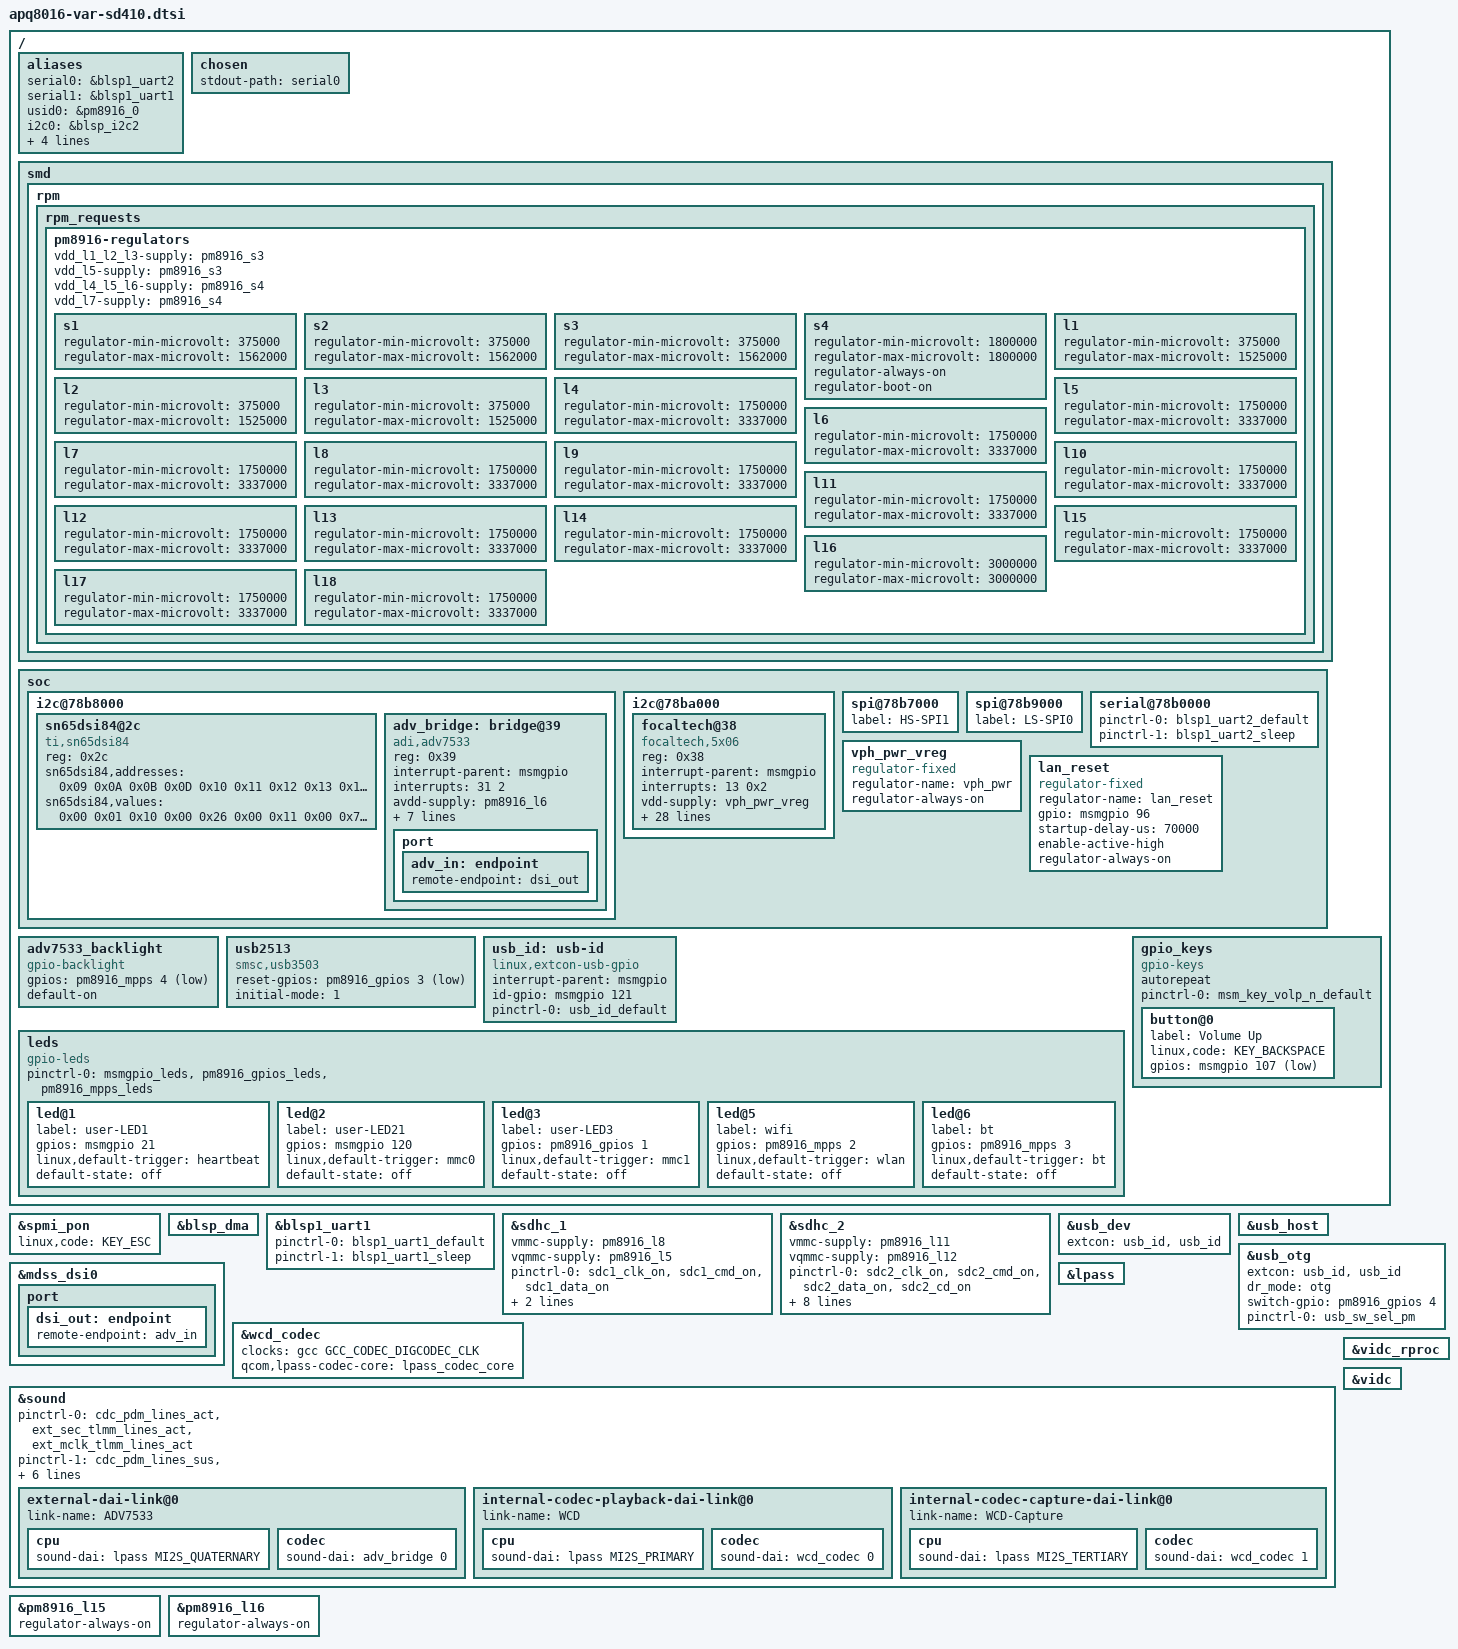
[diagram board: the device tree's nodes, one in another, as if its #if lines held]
/*
/*
 * Copyright (c) 2015, The Linux Foundation. All rights reserved.
 *
 * This program is free software; you can redistribute it and/or modify
 * it under the terms of the GNU General Public License version 2 and
 * only version 2 as published by the Free Software Foundation.
 *
 * This program is distributed in the hope that it will be useful,
 * but WITHOUT ANY WARRANTY; without even the implied warranty of
 * MERCHANTABILITY or FITNESS FOR A PARTICULAR PURPOSE.  See the
 * GNU General Public License for more details.
 */
/* #define HDMI_DISPLAY */
#include <dt-bindings/gpio/gpio.h>
#include <dt-bindings/input/input.h>
#include <dt-bindings/sound/apq8016-lpass.h>
#include "msm8916.dtsi"
#include "pm8916.dtsi"
#include "apq8016-var-sd410-soc-pins.dtsi"
#include "apq8016-var-sd410-pmic-pins.dtsi"
#include "msm8916-mdss.dtsi"
/ {
	aliases {
		serial0 = &blsp1_uart2;
		serial1 = &blsp1_uart1;
		usid0 = &pm8916_0;
		i2c0	= &blsp_i2c2;
		i2c1	= &blsp_i2c6;
		i2c3	= &blsp_i2c4;
		spi0	= &blsp_spi5;
		spi1	= &blsp_spi3;
	};

	chosen {
		stdout-path = "serial0";
	};

	smd {
		rpm {
			rpm_requests {
				pm8916-regulators {

					vdd_l1_l2_l3-supply = <&pm8916_s3>;
					vdd_l5-supply = <&pm8916_s3>;
					vdd_l4_l5_l6-supply = <&pm8916_s4>;
					vdd_l7-supply = <&pm8916_s4>;

					s1 {
						regulator-min-microvolt = <375000>;
						regulator-max-microvolt = <1562000>;
						
					};
					s2 {
						regulator-min-microvolt = <375000>;
						regulator-max-microvolt = <1562000>;
						
					};
					s3 {
						regulator-min-microvolt = <375000>;
						regulator-max-microvolt = <1562000>;
						
					};
					s4 {
						regulator-min-microvolt = <1800000>;
						regulator-max-microvolt = <1800000>;
						
						regulator-always-on;
						regulator-boot-on;
					};

					l1 {
						regulator-min-microvolt = <375000>;
						regulator-max-microvolt = <1525000>;
						
					};
					l2 {
						regulator-min-microvolt = <375000>;
						regulator-max-microvolt = <1525000>;
						
					};
					l3 {
						regulator-min-microvolt = <375000>;
						regulator-max-microvolt = <1525000>;
						
					};
					l4 {
						regulator-min-microvolt = <1750000>;
						regulator-max-microvolt = <3337000>;
						
					};
					l5 {
						regulator-min-microvolt = <1750000>;
						regulator-max-microvolt = <3337000>;
						
					};
					l6 {
						regulator-min-microvolt = <1750000>;
						regulator-max-microvolt = <3337000>;
						
					};
					l7 {
						regulator-min-microvolt = <1750000>;
						regulator-max-microvolt = <3337000>;
						
					};
					l8 {
						regulator-min-microvolt = <1750000>;
						regulator-max-microvolt = <3337000>;
						
					};
					l9 {
						regulator-min-microvolt = <1750000>;
						regulator-max-microvolt = <3337000>;
						
					};
					l10 {
						regulator-min-microvolt = <1750000>;
						regulator-max-microvolt = <3337000>;
						
					};
					l11 {
						regulator-min-microvolt = <1750000>;
						regulator-max-microvolt = <3337000>;
						
					};
					l12 {
						regulator-min-microvolt = <1750000>;
						regulator-max-microvolt = <3337000>;
						
					};
					l13 {
						regulator-min-microvolt = <1750000>;
						regulator-max-microvolt = <3337000>;
						
					};
					l14 {
						regulator-min-microvolt = <1750000>;
						regulator-max-microvolt = <3337000>;
						
					};
					l15 {
						regulator-min-microvolt = <1750000>;
						regulator-max-microvolt = <3337000>;
						
					};
					l16 {
						regulator-min-microvolt = <3000000>;
						regulator-max-microvolt = <3000000>;
						
					};
					l17 {
						regulator-min-microvolt = <1750000>;
						regulator-max-microvolt = <3337000>;
						
					};
					l18 {
						regulator-min-microvolt = <1750000>;
						regulator-max-microvolt = <3337000>;
						
					};
				};
			};
		};
	};

	soc {
		i2c@78b8000 {
			status = "ok";
			sn65dsi84@2c {
				status = "ok";
				compatible = "ti,sn65dsi84";
				reg = <0x2c>;
				sn65dsi84,addresses = <	0x09 0x0A 0x0B 0x0D 0x10 0x11 0x12 0x13 
										0x18 0x19 0x1A 0x1B 0x20 0x21 0x22 0x23 
										0x24 0x25 0x26 0x27 0x28 0x29 0x2A 0x2B 
										0x2C 0x2D 0x2E 0x2F 0x30 0x31 0x32 0x33 
										0x34 0x35 0x36 0x37 0x38 0x39 0x3A 0x3B 
										0x3C 0x3D 0x3E 0x0D>;
				sn65dsi84,values =    <	0x00 0x01 0x10 0x00 0x26 0x00 0x11 0x00 
										0x7a 0x00 0x03 0x00 0x20 0x03 0x00 0x00 
										0x00 0x00 0x00 0x00 0x21 0x00 0x00 0x00 
										0x30 0x00 0x00 0x00 0x03 0x00 0x00 0x00 
										0x28 0x00 0x00 0x00 0x00 0x00 0x00 0x00 
										0x00 0x00 0x00 0x01>;
			};
			
#ifdef HDMI_DISPLAY
			adv_bridge: bridge@39 {
				status = "ok";
				compatible = "adi,adv7533";
				reg = <0x39>;
				interrupt-parent = <&msmgpio>;
				interrupts = <31 2>;
				avdd-supply = <&pm8916_l6>;
				v3p3-supply = <&pm8916_l17>;
				adi,dsi-lanes = <4>;
				pd-gpios = <&msmgpio 32 0>;
				pinctrl-names = "default","sleep";
				pinctrl-0 = <&adv7533_int_active &adv7533_switch_active>;
				pinctrl-1 = <&adv7533_int_suspend &adv7533_switch_suspend>;
				#sound-dai-cells = <1>;

				port {
					adv_in: endpoint {
						remote-endpoint = <&dsi_out>;
					};
				};

			};
#endif
		};

		i2c@78ba000 {
			status = "ok";
			focaltech@38{
				compatible = "focaltech,5x06";
				reg = <0x38>;
				interrupt-parent = <&msmgpio>;
				interrupts = <13 0x2>;
				vdd-supply = <&vph_pwr_vreg>;
				vcc_i2c-supply = <&vph_pwr_vreg>;
				pinctrl-names = "pmx_ts_active","pmx_ts_suspend";
				pinctrl-0 = <&pmx_ts_int_active &pmx_ts_reset_active>;
				pinctrl-1 = <&pmx_ts_int_suspend &pmx_ts_reset_suspend>;
				focaltech,name = "ft5x06";
				focaltech,family-id = <0x54>;
				focaltech,reset-gpio = <&msmgpio 12 0x00>;
				focaltech,irq-gpio = <&msmgpio 13 0x00>;
				focaltech,display-coords = <0 0 800 480>;
				focaltech,hard-reset-delay-ms = <50>;
				focaltech,soft-reset-delay-ms = <50>;
				focaltech,no-force-update;
				focaltech,i2c-pull-up;
				focaltech,group-id = <1>;
				focaltech,hard-reset-delay = <20>;
				focaltech,soft-reset-delay = <150>;
				focaltech,num-max-touches = <2>;
				focaltech,fw-name = "ft_8610_qrd_fw.bin";
				focaltech,fw-delay-aa-ms = <100>;
				focaltech,fw-delay-55-ms = <30>;
				focaltech,fw-upgrade-id1 = <0x79>;
				focaltech,fw-upgrade-id2 = <0x08>;
				focaltech,fw-delay-readid-ms = <10>;
				focaltech,fw-delay-era-flsh-ms = <2000>;
				focaltech,fw-auto-cal;
				focaltech,mirror_h;
				focaltech,mirror_v;
			};
		};

		spi@78b7000 {
			label = "HS-SPI1";
			status = "okay";
		};

		spi@78b9000 {
			label = "LS-SPI0";
			status = "okay";
		};
		serial@78b0000 {
			status = "okay";
			pinctrl-names = "default", "sleep";
			pinctrl-0 = <&blsp1_uart2_default>;
			pinctrl-1 = <&blsp1_uart2_sleep>;
		};
		vph_pwr_vreg: vph_pwr_vreg {

			compatible = "regulator-fixed";
			regulator-name = "vph_pwr";
			status = "ok";
			regulator-always-on;
		}; 
		lan_reset: lan_reset {

			compatible = "regulator-fixed";
			regulator-name = "lan_reset";
	                gpio = <&msmgpio 96 GPIO_ACTIVE_HIGH>;
			startup-delay-us = <70000>;
			enable-active-high;
			regulator-always-on;
			status = "ok";
		}; 
	};
#ifdef HDMI_DISPLAY
	adv7533_backlight: adv7533_backlight {
		compatible = "gpio-backlight";
		gpios = <&pm8916_mpps 4 GPIO_ACTIVE_LOW>;
		default-on;
	};
#else
	backlight: backlight {
		compatible = "gpio-backlight";
		gpios = <&pm8916_mpps 4 GPIO_ACTIVE_HIGH>;
		default-on;
	};
#endif

	usb2513 {
		compatible = "smsc,usb3503";
		reset-gpios = <&pm8916_gpios 3 GPIO_ACTIVE_LOW>;
		initial-mode = <1>;
	};

	usb_id: usb-id {
		interrupt-parent = <&msmgpio>;
		compatible = "linux,extcon-usb-gpio";
		id-gpio = <&msmgpio 121 GPIO_ACTIVE_HIGH>;
		pinctrl-names = "default";
		pinctrl-0 = <&usb_id_default>;
	};

	leds {
		pinctrl-names = "default";
		pinctrl-0 = <&msmgpio_leds>,
			    <&pm8916_gpios_leds>,
			    <&pm8916_mpps_leds>;

		compatible = "gpio-leds";

		led@1 {
			label = "user-LED1";
			gpios = <&msmgpio 21 GPIO_ACTIVE_HIGH>;
			linux,default-trigger = "heartbeat";
			default-state = "off";
		};

		led@2 {
			label = "user-LED21";
			gpios = <&msmgpio 120 GPIO_ACTIVE_HIGH>;
			linux,default-trigger = "mmc0";
			default-state = "off";
		};

		led@3 {
			label = "user-LED3";
			gpios = <&pm8916_gpios 1 GPIO_ACTIVE_HIGH>;
			linux,default-trigger = "mmc1";
			default-state = "off";
		};

		led@5 {
			label = "wifi";
			gpios = <&pm8916_mpps 2 GPIO_ACTIVE_HIGH>;
			linux,default-trigger = "wlan";
			default-state = "off";
		};

		led@6 {
			label = "bt";
			gpios = <&pm8916_mpps 3 GPIO_ACTIVE_HIGH>;
			linux,default-trigger = "bt";
			default-state = "off";
		};
	};

	gpio_keys {
		compatible = "gpio-keys";
		#address-cells = <1>;
		#size-cells = <0>;
		autorepeat;

		pinctrl-names = "default";
		pinctrl-0 = <&msm_key_volp_n_default>;

		button@0 {
			label = "Volume Up";
			linux,code = <KEY_BACKSPACE>;
			gpios = <&msmgpio 107 GPIO_ACTIVE_LOW>;
		};
	};

};

&spmi_pon {
	// Overwrite RESETIN_N keyboard scan code
	linux,code = <KEY_ESC>;
};

&blsp_dma {
	status = "okay";
};

&blsp1_uart1 {
	status = "okay";
	pinctrl-names = "default", "sleep";
	pinctrl-0 = <&blsp1_uart1_default>;
	pinctrl-1 = <&blsp1_uart1_sleep>;
};

&sdhc_1 {
	vmmc-supply = <&pm8916_l8>;
	vqmmc-supply = <&pm8916_l5>;

	pinctrl-names = "default", "sleep";
	pinctrl-0 = <&sdc1_clk_on &sdc1_cmd_on &sdc1_data_on>;
	pinctrl-1 = <&sdc1_clk_off &sdc1_cmd_off &sdc1_data_off>;
	status = "okay";
};

&sdhc_2 {
	vmmc-supply = <&pm8916_l11>;
	vqmmc-supply = <&pm8916_l12>;

	pinctrl-names = "default", "sleep";
	pinctrl-0 = <&sdc2_clk_on &sdc2_cmd_on &sdc2_data_on &sdc2_cd_on>;
	pinctrl-1 = <&sdc2_clk_off &sdc2_cmd_off &sdc2_data_off &sdc2_cd_off>;
	#address-cells = <0>;
	interrupt-parent = <&sdhc_2>;
	interrupts = <0 1 2>;
	#interrupt-cells = <1>;
	interrupt-map-mask = <0xffffffff>;
	interrupt-map = <0 &intc 0 125 0
			1 &intc 0 221 0
			2 &msmgpio 38 0>;
	interrupt-names = "hc_irq", "pwr_irq", "status_irq";
	cd-gpios = <&msmgpio 38 0x1>;

	status = "okay";
};

&usb_dev {
	extcon = <&usb_id>, <&usb_id>;
	status = "okay";
};

&usb_host {
	status = "okay";
};

&sdhc_1 {
	status = "okay";
};

&usb_otg {
	extcon = <&usb_id>, <&usb_id>;
	dr_mode = "otg";
	status = "okay";
	switch-gpio = <&pm8916_gpios 4 GPIO_ACTIVE_HIGH>; // D+/D- lines: 1 - Routed to HUB, 0 - Device
	pinctrl-names = "default";
	pinctrl-0 = <&usb_sw_sel_pm>;
};

#ifdef HDMI_DISPLAY
&mdss_dsi0 {
	status = "ok";

	port {
		dsi_out: endpoint {
			remote-endpoint = <&adv_in>;
		};
	};
};
#else
&mdss_dsi0 {
 	status = "ok";
	panel1:panel@0{
		reg = <0>;
		status = "ok";
		compatible = "sgd,gktw70sdae4sd";
		backlight = <&backlight>;
		
		enable-gpios =<&msmgpio 32 GPIO_ACTIVE_HIGH>;
		pinctrl-names = "default","sleep";
		pinctrl-0 = <&adv7533_switch_active>;
		pinctrl-1 = <&adv7533_switch_suspend>;

		port {
			panel_in: endpoint {
				remote-endpoint = <&dsi0_out>;
			};
		};
	};

	port {
		dsi0_out: endpoint {
			remote-endpoint = <&panel_in>;
		};
	};
};
#endif

&lpass {
	status = "okay";
};

&wcd_codec {
	status = "okay";
	clocks = <&gcc GCC_CODEC_DIGCODEC_CLK>;
	clock-names = "mclk";
	qcom,lpass-codec-core = <&lpass_codec_core>;
};
	/*
	Internal Codec
		playback - Primary MI2S
		capture - Ter MI2S

	External Primary:
		playback - secondary MI2S
		capture - Quat MI2S

	External Secondary:
		playback - Quat MI2S
		capture - Quat MI2S

	*/
&sound {
	status = "okay";
	pinctrl-0 = <&cdc_pdm_lines_act &ext_sec_tlmm_lines_act &ext_mclk_tlmm_lines_act>;
	pinctrl-1 = <&cdc_pdm_lines_sus &ext_sec_tlmm_lines_sus &ext_mclk_tlmm_lines_sus>;
	pinctrl-names = "default", "sleep";
	qcom,model = "DB410c";
	qcom,audio-routing =
		"AMIC1", "MIC BIAS External",
		"AMIC2", "MIC BIAS Internal2",
		"AMIC3", "MIC BIAS External",
		"DMIC1", "MIC BIAS Internal1";

#ifdef HDMI_DISPLAY
	/* External Primary or External Secondary -ADV7533 HDMI */
	external-dai-link@0 {
		link-name = "ADV7533";

		cpu { /* QUAT */
			sound-dai = <&lpass MI2S_QUATERNARY>;
		};
		codec {
			sound-dai = <&adv_bridge 0>;
		};
	};
#endif
	internal-codec-playback-dai-link@0 {		/* I2S - Internal codec */
		link-name = "WCD";
		cpu { /* PRIMARY */
			sound-dai = <&lpass MI2S_PRIMARY>;
		};
		codec {
			sound-dai = <&wcd_codec 0>;
		};
	};

	internal-codec-capture-dai-link@0 {		/* I2S - Internal codec */
		link-name = "WCD-Capture";
		cpu { /* PRIMARY */
			sound-dai = <&lpass MI2S_TERTIARY>;
		};
		codec {
			sound-dai = <&wcd_codec 1>;
		};
	};

};



&pm8916_l15 {
	regulator-always-on;
};

&pm8916_l16{
	status = "ok";
	regulator-always-on;
};

&vidc_rproc {
	status = "okay";
};

&vidc {
	status = "okay";
};
